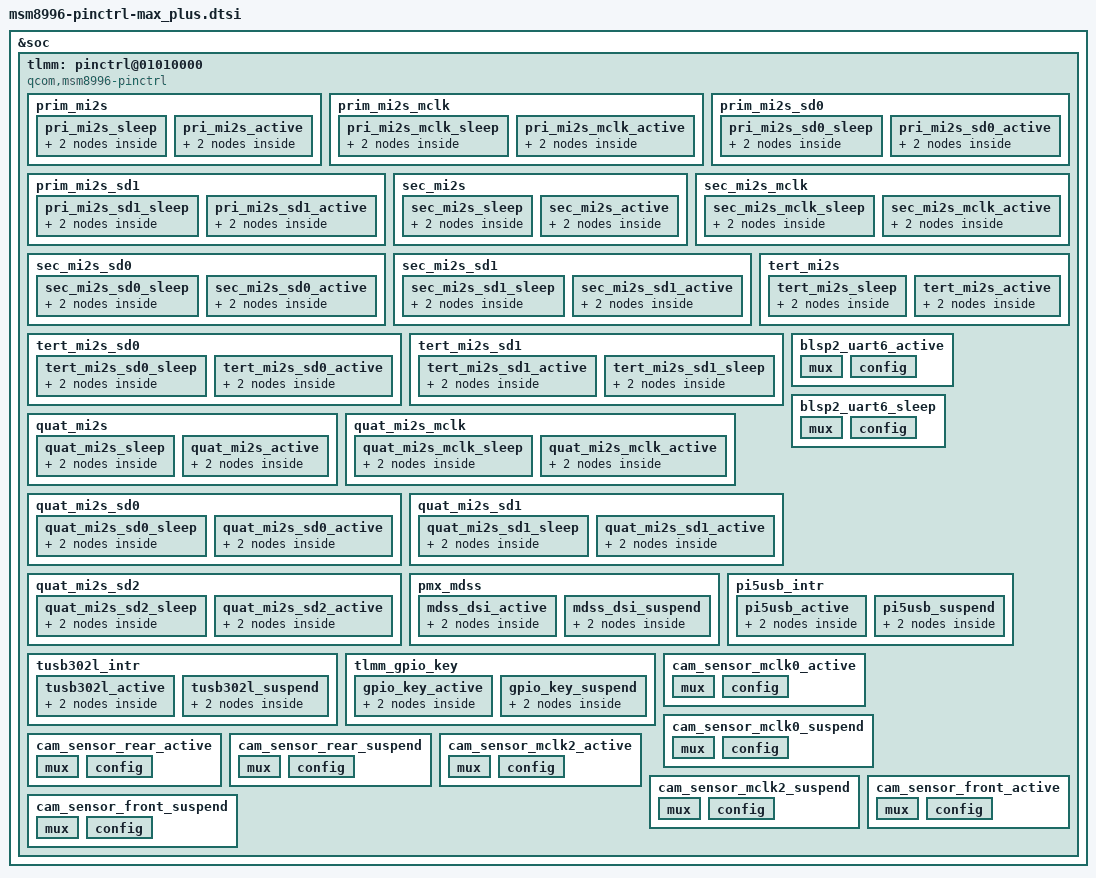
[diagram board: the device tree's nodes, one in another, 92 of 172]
/* Copyright (c) 2014-2015, The Linux Foundation. All rights reserved.
 *
 * This program is free software; you can redistribute it and/or modify
 * it under the terms of the GNU General Public License version 2 and
 * only version 2 as published by the Free Software Foundation.
 *
 * This program is distributed in the hope that it will be useful,
 * but WITHOUT ANY WARRANTY; without even the implied warranty of
 * MERCHANTABILITY or FITNESS FOR A PARTICULAR PURPOSE.  See the
 * GNU General Public License for more details.
 */

&soc {
	tlmm: pinctrl@01010000 {
		compatible = "qcom,msm8996-pinctrl";
		reg = <0x01010000 0x300000>;
		interrupts = <0 208 0>;
		gpio-controller;
		#gpio-cells = <2>;
		interrupt-controller;
		#interrupt-cells = <2>;

/*********** audio MI2S gpio config start ***********/
		prim_mi2s {
			pri_mi2s_sleep: pri_mi2s_sleep {
				mux {
					pins = "gpio65", "gpio66";
					function = "pri_mi2s";
				};
				config {
					pins = "gpio65", "gpio66";
					drive-strength = <2>;   /* 2 mA */
					bias-pull-down;         /* PULL DOWN */
				};
			};
			pri_mi2s_active: pri_mi2s_active {
				mux {
					pins = "gpio65", "gpio66";
					function = "pri_mi2s";
				};
				config {
					pins = "gpio65", "gpio66";
					drive-strength = <8>;   /* 8 mA */
					bias-disable;           /* NO PULL */
					output-high;
				};
			};
		};

		prim_mi2s_mclk {
			pri_mi2s_mclk_sleep: pri_mi2s_mclk_sleep {
				mux {
					pins = "gpio64";
					function = "pri_mi2s";
				};
				config {
					pins = "gpio64";
					drive-strength = <2>;   /* 2 mA */
					bias-pull-down;         /* PULL DOWN */
				};
			};
			pri_mi2s_mclk_active: pri_mi2s_mclk_active {
				mux {
					pins = "gpio64";
					function = "pri_mi2s";
				};
				config {
					pins = "gpio64";
					drive-strength = <8>;   /* 8 mA */
					bias-disable;           /* NO PULL */
					output-high;
				};
			};
		};

		prim_mi2s_sd0 {
			pri_mi2s_sd0_sleep: pri_mi2s_sd0_sleep {
				mux {
					pins = "gpio67";
					function = "pri_mi2s";
				};
				config {
					pins = "gpio67";
					drive-strength = <2>;   /* 2 mA */
					bias-pull-down;         /* PULL DOWN */
				};
			};
			pri_mi2s_sd0_active: pri_mi2s_sd0_active {
				mux {
					pins = "gpio67";
					function = "pri_mi2s";
				};
				config {
					pins = "gpio67";
					drive-strength = <8>;   /* 8 mA */
					bias-disable;           /* NO PULL */
				};
			};
		};

		prim_mi2s_sd1 {
			pri_mi2s_sd1_sleep: pri_mi2s_sd1_sleep {
				mux {
					pins = "gpio68";
					function = "pri_mi2s";
				};
				config {
					pins = "gpio68";
					drive-strength = <2>;   /* 2 mA */
					bias-pull-down;         /* PULL DOWN */
				};
			};
			pri_mi2s_sd1_active: pri_mi2s_sd1_active {
				mux {
					pins = "gpio68";
					function = "pri_mi2s";
				};
				config {
					pins = "gpio68";
					drive-strength = <8>;   /* 8 mA */
					bias-disable;           /* NO PULL */
				};
			};
		};

		sec_mi2s {
			sec_mi2s_sleep: sec_mi2s_sleep {
				mux {
					pins = "gpio80", "gpio81";
					function = "sec_mi2s";
				};
				config {
					pins = "gpio80", "gpio81";
					drive-strength = <2>;   /* 2 mA */
					bias-pull-down;         /* PULL DOWN */
				};
			};
			sec_mi2s_active: sec_mi2s_active {
				mux {
					pins = "gpio80", "gpio81";
					function = "sec_mi2s";
				};
				config {
					pins = "gpio80", "gpio81";
					drive-strength = <8>;   /* 8 mA */
					bias-disable;           /* NO PULL */
					output-high;
				};
			};
		};

		sec_mi2s_mclk {
			sec_mi2s_mclk_sleep: sec_mi2s_mclk_sleep {
				mux {
					pins = "gpio79";
					function = "sec_mi2s";
				};
				config {
					pins = "gpio79";
					drive-strength = <2>;   /* 2 mA */
					bias-pull-down;         /* PULL DOWN */
				};
			};
			sec_mi2s_mclk_active: sec_mi2s_mclk_active {
				mux {
					pins = "gpio79";
					function = "sec_mi2s";
				};
				config {
					pins = "gpio79";
					drive-strength = <8>;   /* 8 mA */
					bias-disable;           /* NO PULL */
					output-high;
				};
			};
		};

		sec_mi2s_sd0 {
			sec_mi2s_sd0_sleep: sec_mi2s_sd0_sleep {
				mux {
					pins = "gpio82";
					function = "sec_mi2s";
				};
				config {
					pins = "gpio82";
					drive-strength = <2>;   /* 2 mA */
					bias-pull-down;         /* PULL DOWN */
				};
			};
			sec_mi2s_sd0_active: sec_mi2s_sd0_active {
				mux {
					pins = "gpio82";
					function = "sec_mi2s";
				};
				config {
					pins = "gpio82";
					drive-strength = <8>;   /* 8 mA */
					bias-disable;           /* NO PULL */
				};
			};
		};

		sec_mi2s_sd1 {
			sec_mi2s_sd1_sleep: sec_mi2s_sd1_sleep {
				mux {
					pins = "gpio83";
					function = "sec_mi2s";
				};
				config {
					pins = "gpio83";
					drive-strength = <2>;   /* 2 mA */
					bias-pull-down;         /* PULL DOWN */
				};
			};
			sec_mi2s_sd1_active: sec_mi2s_sd1_active {
				mux {
					pins = "gpio83";
					function = "sec_mi2s";
				};
				config {
					pins = "gpio83";
					drive-strength = <8>;   /* 8 mA */
					bias-disable;           /* NO PULL */
				};
			};
		};

		tert_mi2s {
			tert_mi2s_sleep: tert_mi2s_sleep {
				mux {
					pins = "gpio75", "gpio76";
					function = "ter_mi2s";
				};

				config {
					pins = "gpio75", "gpio76";
					drive-strength = <2>;   /* 2 mA */
					bias-pull-down;         /* PULL DOWN */
				};
			};
			tert_mi2s_active: tert_mi2s_active {
				mux {
					pins = "gpio75", "gpio76";
					function = "ter_mi2s";
				};

				config {
					pins = "gpio75", "gpio76";
					drive-strength = <8>;   /* 8 mA */
					bias-disable;           /* NO PULL */
					output-high;
				};
			};
		};

		tert_mi2s_sd0 {
			tert_mi2s_sd0_sleep: tert_mi2s_sd0_sleep {
				mux {
					pins = "gpio77";
					function = "ter_mi2s";
				};

				config {
					pins = "gpio77";
					drive-strength = <2>;   /* 2 mA */
					bias-pull-down;         /* PULL DOWN */
				};
			};
			tert_mi2s_sd0_active: tert_mi2s_sd0_active {
				mux {
					pins = "gpio77";
					function = "ter_mi2s";
				};

				config {
					pins = "gpio77";
					drive-strength = <8>;   /* 8 mA */
					bias-disable;           /* NO PULL */
				};
			};
		};

		tert_mi2s_sd1 {
			tert_mi2s_sd1_active: tert_mi2s_sd1_active {
				mux {
					pins = "gpio78";
					function = "ter_mi2s";
				};

				config {
					pins = "gpio78";
					drive-strength = <8>;   /* 8 mA */
					bias-disable;           /* NO PULL */
				};
			};

			tert_mi2s_sd1_sleep: tert_mi2s_sd1_sleep {
				mux {
					pins = "gpio78";
					function = "ter_mi2s";
				};

				config {
					pins = "gpio78";
					drive-strength = <2>;   /* 2 mA */
					bias-pull-down;         /* PULL DOWN */
				};
			};
		};

		quat_mi2s {
			quat_mi2s_sleep: quat_mi2s_sleep {
				mux {
					pins = "gpio58", "gpio59";
					function = "qua_mi2s";
				};

				config {
					pins = "gpio58", "gpio59";
					drive-strength = <2>;   /* 2 mA */
					bias-pull-down;         /* PULL DOWN */
				};
			};
			quat_mi2s_active: quat_mi2s_active {
				mux {
					pins = "gpio58", "gpio59";
					function = "qua_mi2s";
				};

				config {
					pins = "gpio58", "gpio59";
					drive-strength = <8>;   /* 8 mA */
					bias-disable;           /* NO PULL */
					output-high;
				};
			};
		};

		quat_mi2s_mclk {
			quat_mi2s_mclk_sleep: quat_mi2s_mclk_sleep {
				mux {
					pins = "gpio57";
					function = "qua_mi2s";
				};
				config {
					pins = "gpio57";
					drive-strength = <2>;   /* 2 mA */
					bias-pull-down;         /* PULL DOWN */
				};
			};
			quat_mi2s_mclk_active: quat_mi2s_mclk_active {
				mux {
					pins = "gpio57";
					function = "qua_mi2s";
				};
				config {
					pins = "gpio57";
					drive-strength = <8>;   /* 8 mA */
					bias-disable;           /* NO PULL */
					output-high;
				};
			};
		};

		quat_mi2s_sd0 {
			quat_mi2s_sd0_sleep: quat_mi2s_sd0_sleep {
				mux {
					pins = "gpio60";
					function = "qua_mi2s";
				};

				config {
					pins = "gpio60";
					drive-strength = <2>;   /* 2 mA */
					bias-pull-down;         /* PULL DOWN */
				};
			};
			quat_mi2s_sd0_active: quat_mi2s_sd0_active {
				mux {
					pins = "gpio60";
					function = "qua_mi2s";
				};

				config {
					pins = "gpio60";
					drive-strength = <8>;   /* 8 mA */
					bias-disable;           /* NO PULL */
				};
			};
		};

		quat_mi2s_sd1 {
			quat_mi2s_sd1_sleep: quat_mi2s_sd1_sleep {
				mux {
					pins = "gpio61";
					function = "qua_mi2s";
				};
				config {
					pins = "gpio61";
					drive-strength = <2>;   /* 2 mA */
					bias-pull-down;         /* PULL DOWN */
				};
			};
			quat_mi2s_sd1_active: quat_mi2s_sd1_active {
				mux {
					pins = "gpio61";
					function = "qua_mi2s";
				};
				config {
					pins = "gpio61";
					function = "qua_mi2s";
					drive-strength = <8>;   /* 8 mA */
					bias-disable;           /* NO PULL */
				};
			};
		};

		quat_mi2s_sd2 {
			quat_mi2s_sd2_sleep: quat_mi2s_sd2_sleep {
				mux {
					pins = "gpio62";
					function = "qua_mi2s";
				};
				config {
					pins = "gpio62";
					drive-strength = <2>;   /* 2 mA */
					bias-pull-down;         /* PULL DOWN */
				};
			};
			quat_mi2s_sd2_active: quat_mi2s_sd2_active {
				mux {
					pins = "gpio62";
					function = "qua_mi2s";
				};
				config {
					pins = "gpio62";
					drive-strength = <8>;   /* 8 mA */
					bias-disable;           /* NO PULL */
				};
			};
		};
/*********** audio MI2S gpio config end ***********/

/*********** lcd gpio config start ***********/
		pmx_mdss: pmx_mdss {
			mdss_dsi_active: mdss_dsi_active {
				mux {
					pins = "gpio24";
					function = "gpio";
				};

				pmx_mdss {
					pins = "gpio24";
					drive-strength = <8>; /* 8 mA */
					bias-disable = <0>; /* no pull */
					output-high;
				};
			};
			mdss_dsi_suspend: mdss_dsi_suspend {
				mux {
					pins = "gpio24";
					function = "gpio";
				};

				config {
					pins = "gpio24";
					drive-strength = <2>; /* 2 mA */
					bias-pull-down;	/* pull	down */
				};
			};
		};
/*********** lcd gpio config end ***********/

/*********** IR MAXQ616 config start ***********/
blsp2_uart6_active: blsp2_uart6_active {
		mux {
			pins = "gpio85", "gpio86";
			function = "blsp_uart12";
		};

		config {
			pins = "gpio85", "gpio86";
			drive-strength = <2>;
			bias-disable = <0>;
		};
	};

	blsp2_uart6_sleep: blsp2_uart6_sleep {
		mux {
			pins = "gpio85", "gpio86";
			function = "gpio";
		};

		config {
			pins = "gpio85", "gpio86";
			drive-strength = <2>;
			bias_disable = <0>;
			output-low;
		};
	};
/*********** IR MAXQ616 config end ***********/

/*********** usb cc logic gpio config start ***********/
		pi5usb_intr {
			pi5usb_active: pi5usb_active {
				mux {
					pins = "gpio73";
					function = "gpio";
				};

				config {
					pins = "gpio73";
					drive-strength = <2>;
					 bias-pull-up;
				};
			};
			pi5usb_suspend: pi5usb_suspend {
				mux {
					pins = "gpio73";
					function = "gpio";
				};

				config {
					pins = "gpio73";
					drive-strength = <2>;
					 bias-pull-up;
				};
			};
		};

		tusb302l_intr {
			tusb302l_active: tusb302l_active {
				mux {
					pins = "gpio73";
					function = "gpio";
				};

				config {
					pins = "gpio73";
					drive-strength = <2>;
					bias-pull-up;
				};
			};
			tusb302l_suspend: tusb302l_suspend {
				mux {
					pins = "gpio73";
					function = "gpio";
				};

				config {
					pins = "gpio73";
					drive-strength = <2>;
					bias-pull-up;
				};
			};
		};
/*********** usb cc logic gpio config end ***********/

/*********** touch key gpio config start ***********/
		tlmm_gpio_key{
			gpio_key_active: gpio_key_active {
				mux {
					pins = "gpio126";
					function = "gpio";
				};
				config {
					pins = "gpio126";
					drive-strength = <2>;
					bias-pull-up;
				};
			};
			gpio_key_suspend: gpio_key_suspend {
				mux {
					pins = "gpio126";
					function = "gpio";
				};
				config {
					pins = "gpio126";
					drive-strength = <2>;
					bias-pull-up;
				};
			};
		};
/*********** touch key gpio config end ***********/
/*********** Rear/Front Camera config start ***********/
		cam_sensor_mclk0_active: cam_sensor_mclk0_active {
			/* MCLK0 */
			mux {
				/* CLK, DATA */
				pins = "gpio13";
				function = "cam_mclk";
			};

			config {
				pins = "gpio13";
				bias-disable; /* No PULL */
				drive-strength = <2>; /* 2 MA */
			};
		};

		cam_sensor_mclk0_suspend: cam_sensor_mclk0_suspend {
			/* MCLK0 */
			mux {
				/* CLK, DATA */
				pins = "gpio13";
				function = "cam_mclk";
			};

			config {
				pins = "gpio13";
				bias-pull-down; /* PULL DOWN */
				drive-strength = <2>; /* 2 MA */
			};
		};

		cam_sensor_rear_active: cam_sensor_rear_active {
			/* FLASH, AF, STANDBY */
			mux {
				pins = "gpio62", "gpio47", "gpio29";
				function = "gpio";
			};

			config {
				pins = "gpio62", "gpio47", "gpio29";
				bias-disable; /* No PULL */
				drive-strength = <2>; /* 2 MA */
			};
		};

		cam_sensor_rear_suspend: cam_sensor_rear_suspend{
			/* FLASH, AF, STANDBY */
			mux {
				pins = "gpio62", "gpio47", "gpio29";
				function = "gpio";
			};

			config {
				pins = "gpio62", "gpio47", "gpio29";
				bias-disable; /* No PULL */
				drive-strength = <2>; /* 2 MA */
			};
		};

		cam_sensor_mclk2_active: cam_sensor_mclk2_active {
			/* MCLK1 */
			mux {
				/* CLK, DATA */
				pins = "gpio15";
				function = "cam_mclk";
			};

			config {
				pins = "gpio15";
				bias-disable; /* No PULL */
				drive-strength = <2>; /* 2 MA */
			};
		};

		cam_sensor_mclk2_suspend: cam_sensor_mclk2_suspend{
			/* MCLK1 */
			mux {
				/* CLK, DATA */
				pins = "gpio15";
				function = "cam_mclk";
			};

			config {
				pins = "gpio15";
				bias-pull-down; /* PULL DOWN */
				drive-strength = <2>; /* 2 MA */
			};
		};

		cam_sensor_front_active: cam_sensor_front_active{
			/* RESET, STANDBY */
			mux {
				pins = "gpio23","gpio26";
				function = "gpio";
			};

			config {
				pins = "gpio23","gpio26";
				bias-disable; /* No PULL */
				drive-strength = <2>; /* 2 MA */
			};
		};

		cam_sensor_front_suspend: cam_sensor_front_suspend{
			/* RESET, STANDBY */
			mux {
				pins = "gpio23","gpio26";
				function = "gpio";
			};

			config {
				pins = "gpio23","gpio26";
				bias-disable; /* No PULL */
				drive-strength = <2>; /* 2 MA */
			};
		};
/*********** Rear/Front Camera config end ***********/
	};
};
